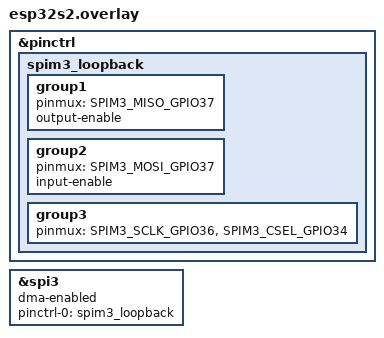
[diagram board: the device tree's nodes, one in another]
/*
 * Copyright (c) 2022 Kumar Gala <galak@kernel.org>
 *
 * SPDX-License-Identifier: Apache-2.0
 */

&pinctrl {
	spim3_loopback: spim3_loopback {
		group1 {
			pinmux = <SPIM3_MISO_GPIO37>;
			output-enable; /* Enable internal loopback */
		};

		group2 {
			pinmux = <SPIM3_MOSI_GPIO37>;
			input-enable; /* Enable internal loopback */
		};

		group3 {
			pinmux = <SPIM3_SCLK_GPIO36>,
				 <SPIM3_CSEL_GPIO34>;
		};
	};
};

#define SPI_LOOPBACK_SLOW_HZ 100000

spi_loopback: &spi3 {
	#address-cells = <1>;
	#size-cells = <0>;
	dma-enabled;
	pinctrl-0 = <&spim3_loopback>;
	pinctrl-names = "default";
	status = "okay";
};

#include "../spi-loopback.dtsi"
